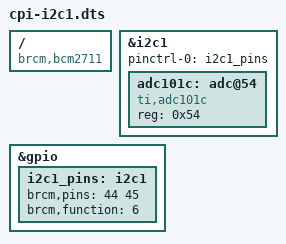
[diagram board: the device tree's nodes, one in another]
/dts-v1/;
/plugin/;

/{
  compatible = "brcm,bcm2711";

  fragment@0 {
    target = <&i2c1>;
    __overlay__ {
      #address-cells = <1>;
      #size-cells = <0>;
      pinctrl-names = "default";
      pinctrl-0 = <&i2c1_pins>;
      status = "okay";

      adc101c: adc@54 {
        reg = <0x54>;
        compatible = "ti,adc101c";
        status = "okay";
      };
    };
  };

  fragment@1 {
    target = <&gpio>;
    __overlay__ {

      i2c1_pins: i2c1 {
        brcm,pins = <44 45>;
        brcm,function = <6>;
      };
    };
  };
};
